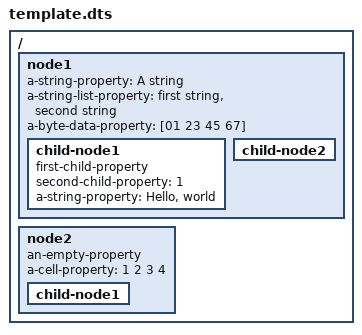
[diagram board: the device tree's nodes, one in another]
/dts-v1/;
/ {
	node1 {
		a-string-property = "A string";
		a-string-list-property = "first string", "second string";
		a-byte-data-property = [01 23 45 67];
		child-node1 {
			first-child-property;
			second-child-property = <1>;
			a-string-property = "Hello, world";
		};
		child-node2 {
		};
	};
	node2 {
		an-empty-property;
		a-cell-property = <1 2 3 4>;	/* each number (cell) is a unit32 */
		child-node1 {
		};
	};
};
